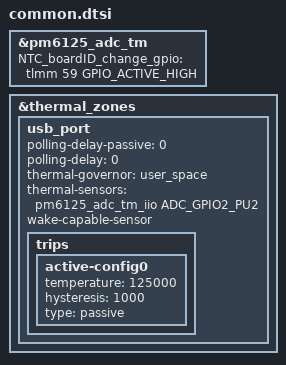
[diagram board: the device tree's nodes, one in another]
#include "../../common/common.dtsi"
#include "huawei_charger.dtsi"
#include "huawei-lcd.dtsi"
#include "huawei-tp.dtsi"
#include "huawei-mmc.dtsi"
#include "huawei_audio.dtsi"
#include "huawei-rgb.dtsi"

&pm6125_adc_tm {
	NTC_boardID_change_gpio = <&tlmm 59 GPIO_ACTIVE_HIGH>;
};

&thermal_zones {
	usb_port {
		polling-delay-passive = <0>;
		polling-delay = <0>;
		thermal-governor = "user_space";
		thermal-sensors = <&pm6125_adc_tm_iio ADC_GPIO2_PU2>;
		wake-capable-sensor;
		trips {
			active-config0 {
				temperature = <125000>;
				hysteresis = <1000>;
				type = "passive";
			};
		};
	};
};

